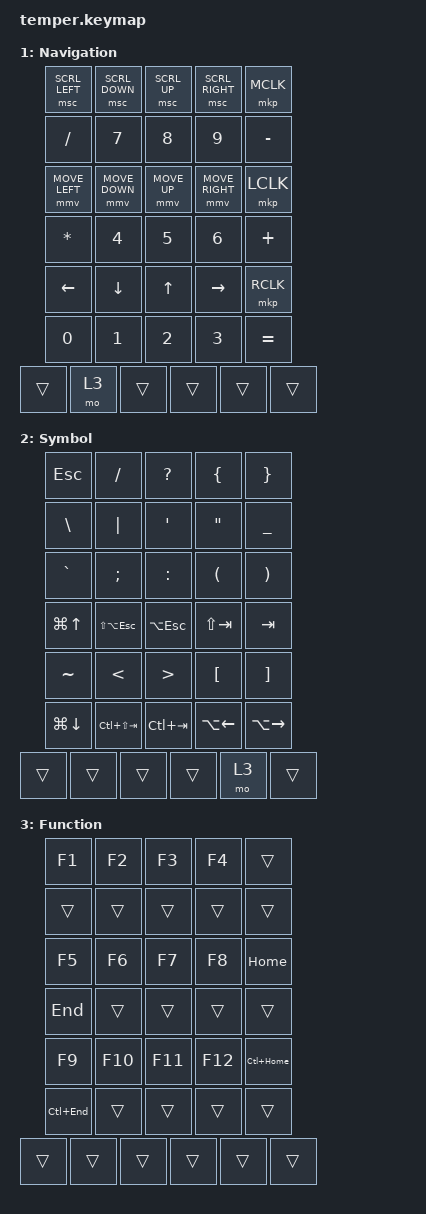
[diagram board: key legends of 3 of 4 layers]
#include <behaviors.dtsi>
#include <dt-bindings/zmk/keys.h>
#include <dt-bindings/zmk/pointing.h>
#include <behaviors/mouse_keys.dtsi>


/ {
    keymap {
        compatible = "zmk,keymap";
        
	default_layer {
            display-name = "Base";
            bindings = <
&kp Q &kp W &kp E &kp R &kp T    &kp Y &kp U &kp I &kp O &kp P
&mt LGUI A &mt LALT S &mt LSHFT D &mt LCTRL F &kp G    &kp H &mt RCTRL J &mt RSHFT K &mt RALT L & mt RGUI ENTER
&kp Z &kp X &kp C &kp V &kp B    &kp N &kp M &kp COMMA &kp DOT &kp DELETE
&bootloader &mo 2 &mt LCTRL SPACE &mt LSHIFT BACKSPACE &mo 1 &bootloader
            >;
        };
	nav {
		display-name = "Navigation";
		bindings = <
&msc SCRL_LEFT &msc SCRL_DOWN &msc SCRL_UP &msc SCRL_RIGHT &mkp MCLK 
	&kp SLASH &kp N7 &kp N8 &kp N9 &kp MINUS
&mmv MOVE_LEFT  &mmv MOVE_DOWN &mmv MOVE_UP &mmv MOVE_RIGHT &mkp LCLK  
	&kp STAR &kp N4 &kp N5 &kp N6 &kp PLUS
&kp LEFT &kp DOWN &kp UP &kp RIGHT &mkp RCLK 
	&kp N0 &kp N1 &kp N2 &kp N3 &kp EQUAL
&trans &mo 3 &trans &trans &trans &trans
		>;
	};
	sym {
		display-name = "Symbol";
		bindings = <
&kp ESC &kp SLASH &kp QMARK &kp LBRC &kp RBRC 
	&kp BSLH &kp PIPE &kp SQT &kp DQT &kp UNDER 
&kp GRAVE &kp SEMI &kp COLON &kp LPAR &kp RPAR
	&kp LG(UP) &kp LS(LA(ESC)) &kp LA(ESC) &kp LS(TAB) &kp TAB
&kp TILDE &kp LT &kp GT &kp LBKT &kp RBKT
	&kp LG(DOWN) &kp LC(LS(TAB)) &kp LC(TAB) &kp LA(LEFT) &kp LA(RIGHT)  
&trans &trans &trans &trans &mo 3 &trans
		>;
	};
	func {
		display-name = "Function";
		bindings = <
&kp F1 &kp F2 &kp F3 &kp F4 &trans 
	&trans &trans &trans &trans &trans 
&kp F5 &kp F6 &kp F7 &kp F8 &kp HOME
	&kp END &trans &trans &trans &trans 
&kp F9 &kp F10 &kp F11 &kp F12 &kp LC(HOME) 
	&kp LC(END) &trans &trans &trans &trans 
&trans &trans &trans &trans &trans &trans
		>;
	};

    };
};
